VERSION "MUR_Dash_CAN_v1.0"

NS_ :

BS_:

BU_: DASH SCREEN

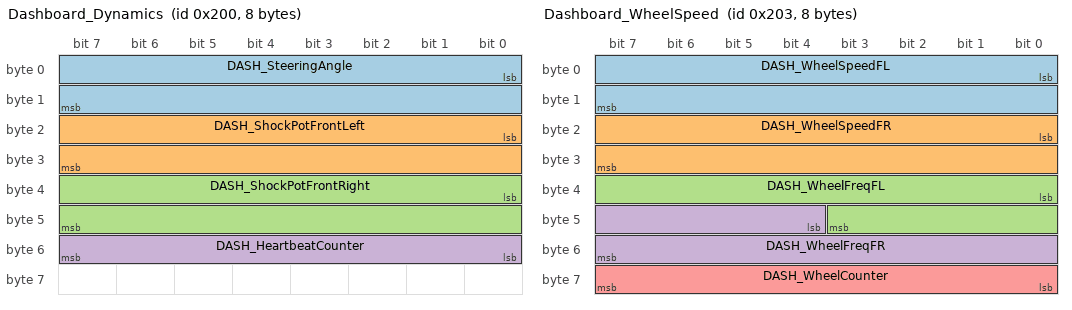
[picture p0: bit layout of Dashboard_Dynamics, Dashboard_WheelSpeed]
BO_ 512 Dashboard_Dynamics: 8 DASH
 SG_ DASH_SteeringAngle : 0|16@1- (0.1,0) [-1800|1800] "deg" SCREEN
 SG_ DASH_ShockPotFrontLeft : 16|16@1+ (0.1,0) [0|500] "mm" SCREEN
 SG_ DASH_ShockPotFrontRight : 32|16@1+ (0.1,0) [0|500] "mm" SCREEN
 SG_ DASH_HeartbeatCounter : 48|8@1+ (1,0) [0|255] "" SCREEN

BO_ 513 Dashboard_Inputs: 4 DASH
 SG_ DASH_ButtonStates : 0|16@1+ (1,0) [0|65535] "" SCREEN
 SG_ DASH_RotarySwitch : 16|8@1+ (1,0) [0|15] "" SCREEN

BO_ 514 Dashboard_Environment: 4 DASH
 SG_ DASH_WindSpeed : 0|16@1+ (0.1,0) [0|6553.5] "m/s" SCREEN

BO_ 515 Dashboard_WheelSpeed: 8 DASH
 SG_ DASH_WheelSpeedFL : 0|16@1+ (0.1,0) [0|6553.4] "rpm" SCREEN
 SG_ DASH_WheelSpeedFR : 16|16@1+ (0.1,0) [0|6553.4] "rpm" SCREEN
 SG_ DASH_WheelFreqFL : 32|12@1+ (1,0) [0|4095] "Hz" SCREEN
 SG_ DASH_WheelFreqFR : 44|12@1+ (1,0) [0|4095] "Hz" SCREEN
 SG_ DASH_WheelCounter : 56|8@1+ (1,0) [0|255] "" SCREEN

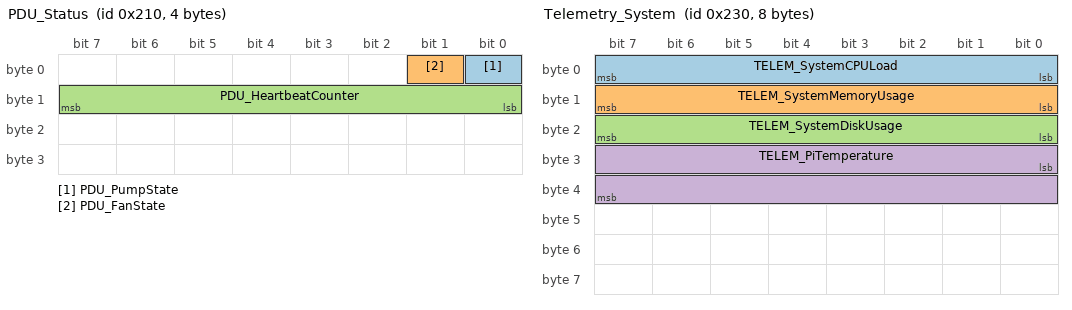
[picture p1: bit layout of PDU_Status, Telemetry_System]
BO_ 528 PDU_Status: 4 DASH
 SG_ PDU_PumpState : 0|1@1+ (1,0) [0|1] "" SCREEN
 SG_ PDU_FanState : 1|1@1+ (1,0) [0|1] "" SCREEN
 SG_ PDU_HeartbeatCounter : 8|8@1+ (1,0) [0|255] "" SCREEN

BO_ 560 Telemetry_System: 8 DASH
 SG_ TELEM_SystemCPULoad : 0|8@1+ (1,0) [0|100] "%" SCREEN
 SG_ TELEM_SystemMemoryUsage : 8|8@1+ (1,0) [0|100] "%" SCREEN
 SG_ TELEM_SystemDiskUsage : 16|8@1+ (1,0) [0|100] "%" SCREEN
 SG_ TELEM_PiTemperature : 24|16@1- (0.1,0) [-3276.8|3276.7] "degC" SCREEN

BO_ 561 Telemetry_LVBattery: 4 DASH
 SG_ TELEM_LVBatteryVoltage : 0|16@1+ (0.01,0) [0|655.35] "V" SCREEN
 SG_ TELEM_LVBatteryCurrent : 16|16@1- (0.1,0) [-3276.8|3276.7] "A" SCREEN

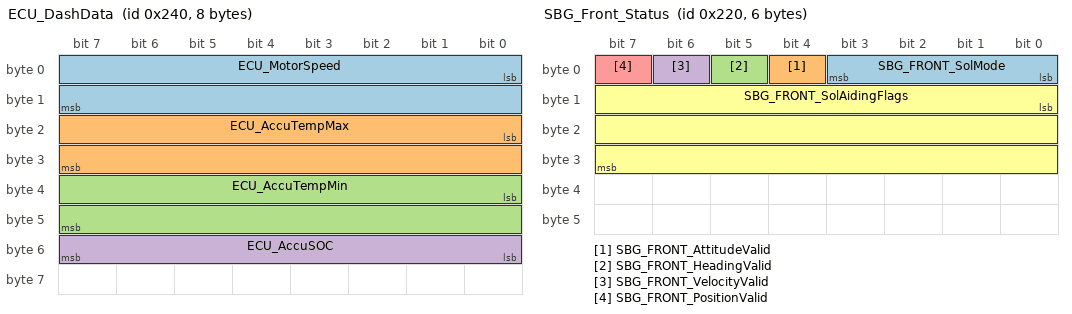
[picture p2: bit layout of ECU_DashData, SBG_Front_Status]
BO_ 576 ECU_DashData: 8 DASH
 SG_ ECU_MotorSpeed : 0|16@1+ (1,0) [0|10000] "rpm" SCREEN
 SG_ ECU_AccuTempMax : 16|16@1- (0.1,0) [-3276.8|3276.7] "degC" SCREEN
 SG_ ECU_AccuTempMin : 32|16@1- (0.1,0) [-3276.8|3276.7] "degC" SCREEN
 SG_ ECU_AccuSOC : 48|8@1+ (1,0) [0|100] "%" SCREEN

BO_ 544 SBG_Front_Status: 6 DASH
 SG_ SBG_FRONT_SolMode : 0|4@1+ (1,0) [0|15] "" SCREEN
 SG_ SBG_FRONT_AttitudeValid : 4|1@1+ (1,0) [0|1] "" SCREEN
 SG_ SBG_FRONT_HeadingValid : 5|1@1+ (1,0) [0|1] "" SCREEN
 SG_ SBG_FRONT_VelocityValid : 6|1@1+ (1,0) [0|1] "" SCREEN
 SG_ SBG_FRONT_PositionValid : 7|1@1+ (1,0) [0|1] "" SCREEN
 SG_ SBG_FRONT_SolAidingFlags : 8|24@1+ (1,0) [0|16777215] "" SCREEN

BO_ 545 SBG_Front_Utc: 8 DASH
 SG_ SBG_FRONT_TimeStamp : 0|32@1+ (1,0) [0|4294967295] "us" SCREEN
 SG_ SBG_FRONT_GpsTow : 32|32@1+ (1,0) [0|4294967295] "ms" SCREEN

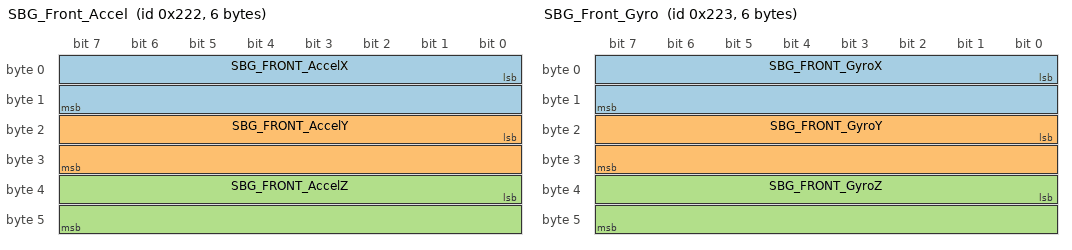
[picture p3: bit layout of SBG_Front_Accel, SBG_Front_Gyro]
BO_ 546 SBG_Front_Accel: 6 DASH
 SG_ SBG_FRONT_AccelX : 0|16@1- (0.01,0) [-327.68|327.67] "m/s^2" SCREEN
 SG_ SBG_FRONT_AccelY : 16|16@1- (0.01,0) [-327.68|327.67] "m/s^2" SCREEN
 SG_ SBG_FRONT_AccelZ : 32|16@1- (0.01,0) [-327.68|327.67] "m/s^2" SCREEN

BO_ 547 SBG_Front_Gyro: 6 DASH
 SG_ SBG_FRONT_GyroX : 0|16@1- (0.001,0) [-32.768|32.767] "rad/s" SCREEN
 SG_ SBG_FRONT_GyroY : 16|16@1- (0.001,0) [-32.768|32.767] "rad/s" SCREEN
 SG_ SBG_FRONT_GyroZ : 32|16@1- (0.001,0) [-32.768|32.767] "rad/s" SCREEN

BO_ 548 SBG_Front_EkfPos: 8 DASH
 SG_ SBG_FRONT_Latitude : 0|32@1- (1E-007,0) [-90|90] "deg" SCREEN
 SG_ SBG_FRONT_Longitude : 32|32@1- (1E-007,0) [-180|180] "deg" SCREEN

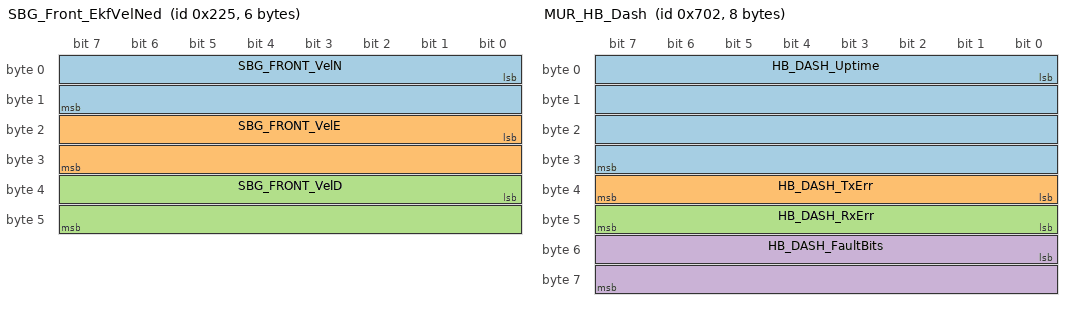
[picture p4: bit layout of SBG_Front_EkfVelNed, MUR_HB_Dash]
BO_ 549 SBG_Front_EkfVelNed: 6 DASH
 SG_ SBG_FRONT_VelN : 0|16@1- (0.01,0) [-327.68|327.67] "m/s" SCREEN
 SG_ SBG_FRONT_VelE : 16|16@1- (0.01,0) [-327.68|327.67] "m/s" SCREEN
 SG_ SBG_FRONT_VelD : 32|16@1- (0.01,0) [-327.68|327.67] "m/s" SCREEN

BO_ 1794 MUR_HB_Dash: 8 DASH
 SG_ HB_DASH_Uptime : 0|32@1+ (1,0) [0|4294967295] "s" SCREEN
 SG_ HB_DASH_TxErr : 32|8@1+ (1,0) [0|255] "" SCREEN
 SG_ HB_DASH_RxErr : 40|8@1+ (1,0) [0|255] "" SCREEN
 SG_ HB_DASH_FaultBits : 48|16@1+ (1,0) [0|65535] "" SCREEN

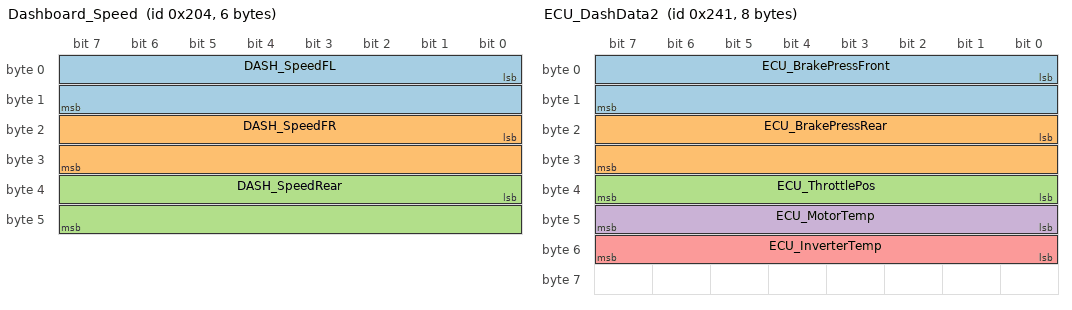
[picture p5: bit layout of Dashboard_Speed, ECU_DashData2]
BO_ 516 Dashboard_Speed: 6 DASH
 SG_ DASH_SpeedFL : 0|16@1+ (0.1,0) [0|6553.4] "km/h" SCREEN
 SG_ DASH_SpeedFR : 16|16@1+ (0.1,0) [0|6553.4] "km/h" SCREEN
 SG_ DASH_SpeedRear : 32|16@1+ (0.1,0) [0|6553.4] "km/h" SCREEN

BO_ 577 ECU_DashData2: 8 DASH
 SG_ ECU_BrakePressFront : 0|16@1+ (0.1,0) [0|2000] "psi" SCREEN
 SG_ ECU_BrakePressRear : 16|16@1+ (0.1,0) [0|2000] "psi" SCREEN
 SG_ ECU_ThrottlePos : 32|8@1+ (1,0) [0|100] "%" SCREEN
 SG_ ECU_MotorTemp : 40|8@1+ (1,-40) [-40|214] "degC" SCREEN
 SG_ ECU_InverterTemp : 48|8@1+ (1,-40) [-40|214] "degC" SCREEN

CM_ "MUR_Dash_CAN_v1.0: NOTE - IDs 512, 513, 514, 515, 516, 544-549 (front SBG), 576, 577 and 1794 intentionally mirror the definitions in the Sensor/Telemetry CAN DBC. Ensure bus separation is maintained during combined logging to prevent collisions.";
CM_ BU_ DASH "Dashboard Sensor Node - acts as gateway, forwarding CAN frames to the display.";
CM_ BU_ SCREEN "CANchecked MFD28 Gen2 display (2026-10) - sole receiver on this physical bus. Set it to 1000 kbit/s (Setup > Can Bus > Can Speed; it also does 125/250/500) to match the dashboard node, and CanTerm on: it is one end of a two-node bus, the dashboard board is the other. It reads this DBC through CANchecked DSS (TRI Editor > import DBC), where each signal becomes a sensor with a 15-character name limit. It can also transmit (Can Switch, Custom Can Frames); keep both off, nothing listens. It shows any value it is sent, so the invalid sentinels documented per signal display as numbers - handle them with DSS warning limits until the firmware has a validity scheme.";
CM_ BO_ 512 "Dashboard steering/suspension + heartbeat. Transmit rate 100 Hz (FAST).";
CM_ SG_ 512 DASH_SteeringAngle "Signed to allow left/right steering deflection.";
CM_ BO_ 513 "Dashboard driver button states + rotary mode switch. Transmit rate 20 Hz.";
CM_ SG_ 513 DASH_ButtonStates "Bit-per-button. Exact button map TBD - to be locked down with driver interface design per Telemetry_CAN.md notes.";
CM_ SG_ 513 DASH_RotarySwitch "Rotary switch position index (0-15). ASSUMPTION - confirm number of switch positions.";
CM_ BO_ 514 "Dashboard wind speed sensor. Transmit rate 10 Hz (MEDIUM).";
CM_ BO_ 515 "MUR ADDITION (PROVISIONAL): front wheel speeds from the two encoder DINs on the dashboard node (DIN[3] PC13 = FL, DIN[8] PC5 = FR), measured by EXTI edge timing (firmware/lib/dash/dash_wheel). Transmit rate 100 Hz (FAST).";
CM_ SG_ 515 DASH_WheelSpeedFL "Wheel rpm = pulse frequency x 60 / pulses-per-rev. 0xFFFF (6553.5) = invalid: encoder pulses-per-rev not calibrated yet (TODO(calib)) - read DASH_WheelFreqFL instead. 0 after ~0.5 s with no pulse.";
CM_ SG_ 515 DASH_WheelSpeedFR "See DASH_WheelSpeedFL.";
CM_ SG_ 515 DASH_WheelFreqFL "Raw encoder pulse frequency, independent of any calibration - the bench/sanity view. Saturates at 4095 (= at least 4095 Hz).";
CM_ SG_ 515 DASH_WheelFreqFR "See DASH_WheelFreqFL.";
CM_ SG_ 515 DASH_WheelCounter "Increments every frame; a frozen counter means a stalled node.";
CM_ BO_ 528 "PDU pump/fan on-off state + heartbeat. Transmit rate 10 Hz (SLOW). Byte 2 reserved for future PDU_FanSpeed once speed control is implemented (see Telemetry_CAN.md).";
CM_ BO_ 560 "Telemetry Pi system health (CPU/mem/disk/temp), broadcast for dashboard display. Transmit rate 5 Hz.";
CM_ BO_ 561 "Telemetry Pi LV battery voltage/current monitoring. Transmit rate 2 Hz (SLOW).";
CM_ BO_ 576 "MUR ADDITION (PROVISIONAL): the ECU's Telemetry CAN ECU_DashData, forwarded unchanged by the dashboard. Transmit rate 10 Hz (the ECU's best-effort thread). 8 bytes from day one; byte 7 is still reserved: add new display signals there, byte-aligned and 8 or 16 bits wide so the MFD28's DSS import reads them cleanly, and never move, resize or rescale an existing one. The dashboard forwards this frame to Dash CAN byte-for-byte, so it must stay identical in mur_dashboard_can.dbc (scripts/validate.py checks); adding a signal then needs no dashboard firmware change.";
CM_ SG_ 576 ECU_MotorSpeed "Motor speed magnitude in rpm, from the inverter's INV_MotorPosition on Tractive CAN, clipped to 0-10000 by the ECU; no direction. 0xFFFF = invalid: the ECU has not heard the inverter yet, or has lost it (comms timeout).";
CM_ SG_ 576 ECU_AccuTempMax "Canonical car accumulator maximum, converted by ECU using voltage recovery and Table 5. Prefer complete fresh sweeps; if no sweep frames are fresh, use a fresh mapped summary maximum (1 degC input resolution). Partial or invalid live sweeps prevent fallback. 0x7FFF is invalid. Identical ECU_DashData bytes reach TTCS on Control CAN and screen on Telemetry/Dash CAN.";
CM_ SG_ 576 ECU_AccuTempMin "Corrected minimum from complete fresh sensor sweeps. 0x7FFF is invalid, including during summary-maximum fallback; summary supplies no minimum.";
CM_ SG_ 576 ECU_AccuSOC "MUR ADDITION (PROVISIONAL): accumulator state of charge from the ENNOID BMS's summary frame on Tractive CAN, its 0-255 byte rescaled to whole percent by firmware/lib/ennoid. 0xFF = invalid: the ECU has not heard the BMS yet, or has lost it (comms timeout). Only as good as the BMS's own capacity setting, which was wrong at last check (2000 Ah, reading about 10 %).";
CM_ BO_ 544 "MUR ADDITION (PROVISIONAL): the front SBG Ellipse-D's Telemetry CAN frame, forwarded unchanged by the dashboard (rear unit not forwarded). Layout, names and rate are vendor/SBG_Ellipse.dbc's, and must stay identical to it (scripts/validate.py FORWARDED). SBG_ECAN_MSG_STATUS_03 (SBG default ID 0x102), front unit. Bytes 4-5 are HEAVE_STATUS (ship-motion status, meaningless on a car) - left undefined.";
CM_ BO_ 545 "MUR ADDITION (PROVISIONAL): the front SBG Ellipse-D's Telemetry CAN frame, forwarded unchanged by the dashboard (rear unit not forwarded). Layout, names and rate are vendor/SBG_Ellipse.dbc's, and must stay identical to it (scripts/validate.py FORWARDED). SBG_ECAN_MSG_UTC_0 (SBG default ID 0x110), front unit. TimeStamp is time since the unit powered up; GpsTow is GPS time of week - use it to line up the two units and other logs.";
CM_ BO_ 546 "MUR ADDITION (PROVISIONAL): the front SBG Ellipse-D's Telemetry CAN frame, forwarded unchanged by the dashboard (rear unit not forwarded). Layout, names and rate are vendor/SBG_Ellipse.dbc's, and must stay identical to it (scripts/validate.py FORWARDED). SBG_ECAN_MSG_IMU_ACCEL (SBG default ID 0x121), front unit. Calibrated accelerometer, sensor body frame.";
CM_ BO_ 547 "MUR ADDITION (PROVISIONAL): the front SBG Ellipse-D's Telemetry CAN frame, forwarded unchanged by the dashboard (rear unit not forwarded). Layout, names and rate are vendor/SBG_Ellipse.dbc's, and must stay identical to it (scripts/validate.py FORWARDED). SBG_ECAN_MSG_IMU_GYRO (SBG default ID 0x122), front unit. Calibrated gyro, sensor body frame.";
CM_ BO_ 548 "MUR ADDITION (PROVISIONAL): the front SBG Ellipse-D's Telemetry CAN frame, forwarded unchanged by the dashboard (rear unit not forwarded). Layout, names and rate are vendor/SBG_Ellipse.dbc's, and must stay identical to it (scripts/validate.py FORWARDED). SBG_ECAN_MSG_EKF_POS (SBG default ID 0x134), front unit. WGS84 latitude/longitude from the INS solution; invalid until SolMode = NavPosition.";
CM_ BO_ 549 "MUR ADDITION (PROVISIONAL): the front SBG Ellipse-D's Telemetry CAN frame, forwarded unchanged by the dashboard (rear unit not forwarded). Layout, names and rate are vendor/SBG_Ellipse.dbc's, and must stay identical to it (scripts/validate.py FORWARDED). SBG_ECAN_MSG_EKF_VEL_NED (SBG default ID 0x137), front unit. INS velocity in the North/East/Down frame, not the car frame.";
CM_ SG_ 544 SBG_FRONT_SolMode "SOLUTION_STATUS bits 0-3: EKF solution mode. Nothing but NavPosition means position/velocity are trustworthy.";
CM_ SG_ 544 SBG_FRONT_SolAidingFlags "SOLUTION_STATUS bits 8-31: aiding-used flags, SBG_ECOM_SOL_* bit N maps to bit N-8 here (e.g. bit 11 GPS1_POS_USED -> bit 3, bit 27 ALIGN_VALID -> bit 19). See sbgECom doc/binaryMessages.md SOLUTION_STATUS.";
CM_ BO_ 516 "MUR ADDITION (PROVISIONAL): wheel speeds in km/h for the driver's screen, computed on the dashboard node (firmware/lib/dash/dash_speed) and sent with identical bytes on Telemetry and Dash CAN (scripts/validate.py FORWARDED keeps the two definitions the same). Transmit rate 20 Hz. Same equations as mur-embedded's tools/bench/mur_can.py: 0.0766 km/h per wheel rpm (a 16 in tyre, assumed from the factor, not measured on the car).";
CM_ SG_ 516 DASH_SpeedFL "Front left wheel km/h = DASH_WheelSpeedFL x 0.0766. 0xFFFF (6553.5) = invalid whenever DASH_WheelSpeedFL is.";
CM_ SG_ 516 DASH_SpeedFR "Front right wheel km/h; see DASH_SpeedFL.";
CM_ SG_ 516 DASH_SpeedRear "Rear wheel km/h from motor speed, there being no rear wheel sensor: ECU_MotorSpeed / (39/9, the 9:39 chain drive) x 0.0766. The diff makes it the average of the two rear wheels, so it reads a little off from either one in a corner. 0xFFFF (6553.5) = invalid: ECU_MotorSpeed is invalid, or the dashboard has had no ECU_DashData for 500 ms.";
CM_ BO_ 577 "MUR ADDITION (PROVISIONAL): more driver-display data from the ECU, ECU_DashData being full: brake pressures and throttle from the pedalbox's Pedal_Status, motor and inverter temperatures from the inverter, all on Tractive CAN. Transmit rate 10 Hz (the ECU's best-effort thread). The dashboard forwards it to Dash CAN byte-for-byte, so it must stay identical in mur_dashboard_can.dbc (scripts/validate.py FORWARDED). Byte 7 reserved: add display signals there, byte-aligned and 8 or 16 bits wide, never moving, resizing or rescaling an existing one.";
CM_ SG_ 577 ECU_BrakePressFront "PEDAL_BrakePressure1 (front circuit) as the ECU last received it. 0xFFFF (6553.5) = invalid: the ECU has not heard Pedal_Status yet, or it has timed out or frozen (the ECU's pedal comm_err).";
CM_ SG_ 577 ECU_BrakePressRear "PEDAL_BrakePressure2 (rear circuit); see ECU_BrakePressFront.";
CM_ SG_ 577 ECU_ThrottlePos "Accelerator pedal: the mean of PEDAL_Position1 and PEDAL_Position2, rounded to whole %. Shown even when the two disagree; APPS plausibility is the ECU's fault logic, not the screen's. 0xFF = invalid, as for ECU_BrakePressFront.";
CM_ SG_ 577 ECU_MotorTemp "Motor temperature, whole degC, from the inverter's INV_MotorRawTemp (its motor temperature input). Offset -40: raw 0 = -40 degC, clamped to -40..214. 0xFF (215) = invalid: the ECU has not heard the inverter, has lost it (comms timeout), or the inverter reports its 1381 sensor-fault value.";
CM_ SG_ 577 ECU_InverterTemp "Inverter temperature: the hottest of its three IGBT module temperatures (INV_ModuleA/B/CTemp), whole degC, offset -40, clamped to -40..214. 0xFF (215) = invalid: the ECU has not heard the inverter, or has lost it.";
CM_ BO_ 1794 "MUR ADDITION (PROVISIONAL): 1 Hz dashboard node heartbeat, ID 0x700 + node id (Dashboard = 2). Uptime, CAN error counters, low 16 bits of latched fault mask. Signals node-prefixed for bus-wide uniqueness.";

BA_DEF_ BO_ "GenMsgCycleTime" INT 0 100000;
BA_DEF_ BO_ "GenMsgSendType" ENUM "Cyclic","OnChange","Event";
BA_DEF_ "BusType" STRING ;
BA_DEF_DEF_ "GenMsgCycleTime" 0;
BA_DEF_DEF_ "GenMsgSendType" "Cyclic";
BA_DEF_DEF_ "BusType" "CAN";
BA_ "GenMsgCycleTime" BO_ 512 10;
BA_ "GenMsgCycleTime" BO_ 513 50;
BA_ "GenMsgCycleTime" BO_ 514 100;
BA_ "GenMsgCycleTime" BO_ 515 10;
BA_ "GenMsgCycleTime" BO_ 528 100;
BA_ "GenMsgCycleTime" BO_ 560 200;
BA_ "GenMsgCycleTime" BO_ 561 500;
BA_ "GenMsgCycleTime" BO_ 576 100;
BA_ "GenMsgCycleTime" BO_ 544 100;
BA_ "GenMsgCycleTime" BO_ 545 1000;
BA_ "GenMsgCycleTime" BO_ 546 10;
BA_ "GenMsgCycleTime" BO_ 547 10;
BA_ "GenMsgCycleTime" BO_ 548 100;
BA_ "GenMsgCycleTime" BO_ 549 20;
BA_ "GenMsgCycleTime" BO_ 516 50;
BA_ "GenMsgCycleTime" BO_ 577 100;
BA_ "GenMsgCycleTime" BO_ 1794 1000;

VAL_ 544 SBG_FRONT_SolMode 0 "Uninitialized" 1 "VerticalGyro" 2 "AHRS" 3 "NavVelocityDeprecated" 4 "NavPosition" ;
